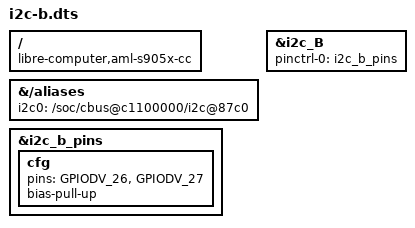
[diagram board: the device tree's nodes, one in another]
// SPDX-License-Identifier: (GPL-2.0-or-later OR MIT)
/*
 * Copyright (c) 2017 BayLibre, SAS.
 * Author: Neil Armstrong <narmstrong@baylibre.com>
 */
/*
 * Summary: I2C_B on Header 7J1
 *
 * Pins (Header.Pin  Name  Pad  Ref — cross-ref gpio.map):
 *   7J1.27   GPIODV_26     E2      I2C_SDA_A
 *   7J1.28   GPIODV_27     F3      I2C_SCK_A
 * Resource-provides: bus:i2c_B
 */
/dts-v1/;
/plugin/;

/ {
	compatible = "libre-computer,aml-s905x-cc",
		"libretech,aml-s905x-cc",
		"libre-computer,aml-s905x-cc-v2",
		"libretech,aml-s905x-cc-v2",
		"amlogic,s905x",
		"amlogic,meson-gxl";
fragment@0 {
		target-path = "/aliases";

		__overlay__ {
			i2c0 = "/soc/cbus@c1100000/i2c@87c0";
		};
	};

	fragment@1 {
		target = <&i2c_b_pins>;

		__overlay__ {
			cfg {
				pins = "GPIODV_26", "GPIODV_27";
				bias-pull-up;
			};
		};
	};

	fragment@2 {
		target = <&i2c_B>;
		
		__overlay__ {
			status = "okay";
			pinctrl-0 = <&i2c_b_pins>;
			pinctrl-names = "default";
		};
	};
};
